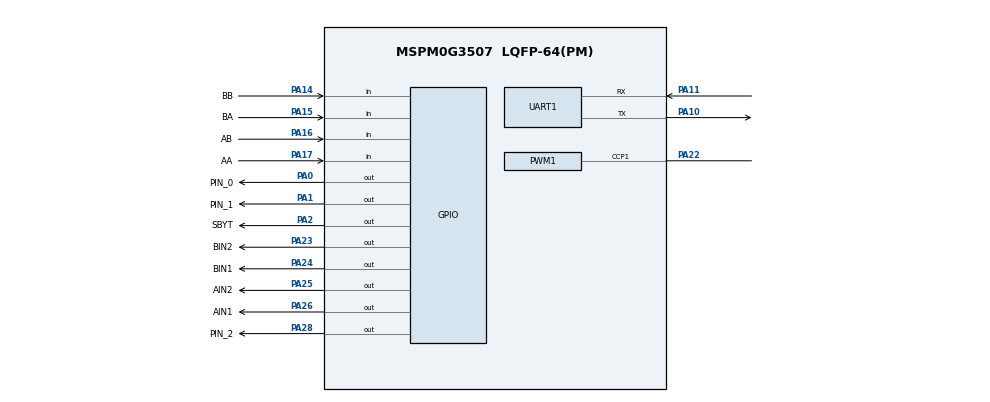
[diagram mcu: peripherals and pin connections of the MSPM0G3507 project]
/**
 * These arguments were used when this file was generated. They will be automatically applied on subsequent loads
 * via the GUI or CLI. Run CLI with '--help' for additional information on how to override these arguments.
 * @cliArgs --device "MSPM0G350X" --part "Default" --package "LQFP-64(PM)" --product "mspm0_sdk@2.10.00.04"
 * @v2CliArgs --device "MSPM0G3507" --package "LQFP-64(PM)" --product "mspm0_sdk@2.10.00.04"
 * @versions {"tool":"1.26.2+4477"}
 */

/**
 * Import the modules used in this configuration.
 */
const ADC12   = scripting.addModule("/ti/driverlib/ADC12", {}, false);
const ADC121  = ADC12.addInstance();
const GPIO    = scripting.addModule("/ti/driverlib/GPIO", {}, false);
const GPIO1   = GPIO.addInstance();
const GPIO2   = GPIO.addInstance();
const GPIO3   = GPIO.addInstance();
const PWM     = scripting.addModule("/ti/driverlib/PWM", {}, false);
const PWM1    = PWM.addInstance();
const SYSCTL  = scripting.addModule("/ti/driverlib/SYSCTL");
const SYSTICK = scripting.addModule("/ti/driverlib/SYSTICK");
const UART    = scripting.addModule("/ti/driverlib/UART", {}, false);
const UART1   = UART.addInstance();

/**
 * Write custom configuration values to the imported modules.
 */
ADC121.$name               = "ADC12_0";
ADC121.repeatMode          = true;
ADC121.adcMem0_name        = "ADC_CH0";
ADC121.sampClkDiv          = "DL_ADC12_CLOCK_DIVIDE_8";
ADC121.enabledInterrupts   = ["DL_ADC12_INTERRUPT_MEM0_RESULT_LOADED"];
ADC121.sampleTime0         = "2us";
ADC121.peripheral.$assign  = "ADC0";
ADC121.adcPin0Config.$name = "ti_driverlib_gpio_GPIOPinGeneric0";

const Board = scripting.addModule("/ti/driverlib/Board", {}, false);

GPIO1.$name                         = "Gray_Address";
GPIO1.associatedPins.create(3);
GPIO1.associatedPins[0].$name       = "PIN_0";
GPIO1.associatedPins[0].pin.$assign = "PA0";
GPIO1.associatedPins[1].$name       = "PIN_1";
GPIO1.associatedPins[1].pin.$assign = "PA1";
GPIO1.associatedPins[2].$name       = "PIN_2";
GPIO1.associatedPins[2].pin.$assign = "PA28";

GPIO2.$name                         = "MOTOR";
GPIO2.associatedPins.create(5);
GPIO2.associatedPins[0].$name       = "AIN1";
GPIO2.associatedPins[0].pin.$assign = "PA26";
GPIO2.associatedPins[1].$name       = "AIN2";
GPIO2.associatedPins[1].pin.$assign = "PA25";
GPIO2.associatedPins[2].$name       = "BIN1";
GPIO2.associatedPins[2].pin.$assign = "PA24";
GPIO2.associatedPins[3].$name       = "BIN2";
GPIO2.associatedPins[3].pin.$assign = "PA23";
GPIO2.associatedPins[4].$name       = "SBYT";
GPIO2.associatedPins[4].pin.$assign = "PA2";

GPIO3.$name                              = "encoder";
GPIO3.associatedPins.create(4);
GPIO3.associatedPins[0].$name            = "AA";
GPIO3.associatedPins[0].direction        = "INPUT";
GPIO3.associatedPins[0].internalResistor = "PULL_DOWN";
GPIO3.associatedPins[0].pin.$assign      = "PA17";
GPIO3.associatedPins[1].$name            = "AB";
GPIO3.associatedPins[1].direction        = "INPUT";
GPIO3.associatedPins[1].internalResistor = "PULL_DOWN";
GPIO3.associatedPins[1].pin.$assign      = "PA16";
GPIO3.associatedPins[2].$name            = "BA";
GPIO3.associatedPins[2].direction        = "INPUT";
GPIO3.associatedPins[2].internalResistor = "PULL_DOWN";
GPIO3.associatedPins[2].pin.$assign      = "PA15";
GPIO3.associatedPins[3].$name            = "BB";
GPIO3.associatedPins[3].direction        = "INPUT";
GPIO3.associatedPins[3].internalResistor = "PULL_DOWN";
GPIO3.associatedPins[3].pin.$assign      = "PA14";

PWM1.$name                              = "PWM_MOTOR";
PWM1.timerStartTimer                    = true;
PWM1.pwmMode                            = "EDGE_ALIGN_UP";
PWM1.peripheral.ccp1Pin.$assign         = "PA22";
PWM1.PWM_CHANNEL_0.$name                = "ti_driverlib_pwm_PWMTimerCC0";
PWM1.PWM_CHANNEL_0.dutyCycle            = 20;
PWM1.PWM_CHANNEL_1.$name                = "ti_driverlib_pwm_PWMTimerCC1";
PWM1.PWM_CHANNEL_1.dutyCycle            = 20;
PWM1.ccp0PinConfig.direction            = scripting.forceWrite("OUTPUT");
PWM1.ccp0PinConfig.hideOutputInversion  = scripting.forceWrite(false);
PWM1.ccp0PinConfig.onlyInternalResistor = scripting.forceWrite(false);
PWM1.ccp0PinConfig.passedPeripheralType = scripting.forceWrite("Digital");
PWM1.ccp0PinConfig.$name                = "ti_driverlib_gpio_GPIOPinGeneric3";
PWM1.ccp1PinConfig.direction            = scripting.forceWrite("OUTPUT");
PWM1.ccp1PinConfig.hideOutputInversion  = scripting.forceWrite(false);
PWM1.ccp1PinConfig.onlyInternalResistor = scripting.forceWrite(false);
PWM1.ccp1PinConfig.passedPeripheralType = scripting.forceWrite("Digital");
PWM1.ccp1PinConfig.$name                = "ti_driverlib_gpio_GPIOPinGeneric4";

SYSCTL.forceDefaultClkConfig = true;
SYSCTL.clockTreeEn           = true;

SYSTICK.periodEnable    = true;
SYSTICK.interruptEnable = true;
SYSTICK.systickEnable   = true;
SYSTICK.period          = 32000;

UART1.$name                    = "UART_0";
UART1.targetBaudRate           = 115200;
UART1.peripheral.rxPin.$assign = "PA11";
UART1.peripheral.txPin.$assign = "PA10";
UART1.txPinConfig.$name        = "ti_driverlib_gpio_GPIOPinGeneric1";
UART1.rxPinConfig.$name        = "ti_driverlib_gpio_GPIOPinGeneric2";

/**
 * Pinmux solution for unlocked pins/peripherals. This ensures that minor changes to the automatic solver in a future
 * version of the tool will not impact the pinmux you originally saw.  These lines can be completely deleted in order to
 * re-solve from scratch.
 */
ADC121.peripheral.adcPin0.$suggestSolution = "PA27";
Board.peripheral.$suggestSolution          = "DEBUGSS";
Board.peripheral.swclkPin.$suggestSolution = "PA20";
Board.peripheral.swdioPin.$suggestSolution = "PA19";
PWM1.peripheral.$suggestSolution           = "TIMA0";
PWM1.peripheral.ccp0Pin.$suggestSolution   = "PA21";
UART1.peripheral.$suggestSolution          = "UART0";
